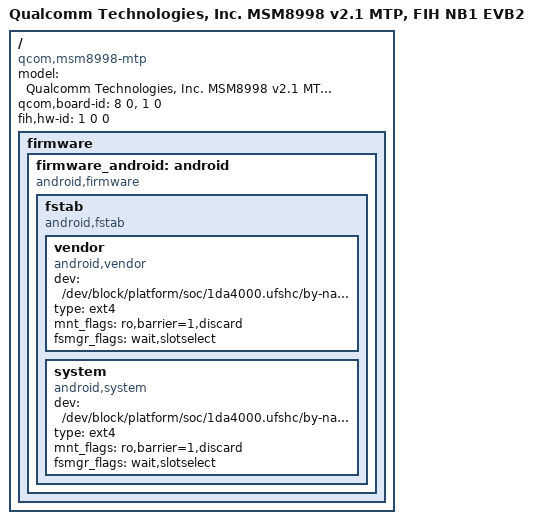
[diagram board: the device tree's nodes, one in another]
/dts-v1/;
/plugin/;

#include "../qcom/msm8998.dtsi"
#include "../qcom/msm8998-mdss-panels.dtsi"
#include "../qcom/msm8998-mtp.dtsi"

/ {
	model = "Qualcomm Technologies, Inc. MSM8998 v2.1 MTP, FIH NB1 EVB2";
	compatible = "qcom,msm8998-mtp", "qcom,msm8998", "qcom,mtp";
	qcom,board-id = <8 0>, <1 0>;
	fih,hw-id = <1 0 0>;

	firmware {
		firmware_android: android {};
	};
};

&firmware_android {
	compatible = "android,firmware";
	fstab {
		compatible = "android,fstab";
		vendor {
			compatible = "android,vendor";
			dev = "/dev/block/platform/soc/1da4000.ufshc/by-name/vendor";
			type = "ext4";
			mnt_flags = "ro,barrier=1,discard";
			fsmgr_flags = "wait,slotselect";
			status = "ok";
		};

		system {
			compatible = "android,system";
			dev = "/dev/block/platform/soc/1da4000.ufshc/by-name/system";
			type = "ext4";
			mnt_flags = "ro,barrier=1,discard";
			fsmgr_flags = "wait,slotselect";
			status = "ok";
		};
	};
};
